# MK70F15WS register map
File version: 1.6
Registers are 32-bit, read-write, reset 0x0 unless marked. A register's access mark holds for its fields unless they carry their own. Offsets are from the block's base; [hi:lo] are bit positions; {n}, {i} and the like mark numbered series.

## SIM — System Integration Module
Base 0x40047000; register names take the prefix SIM_
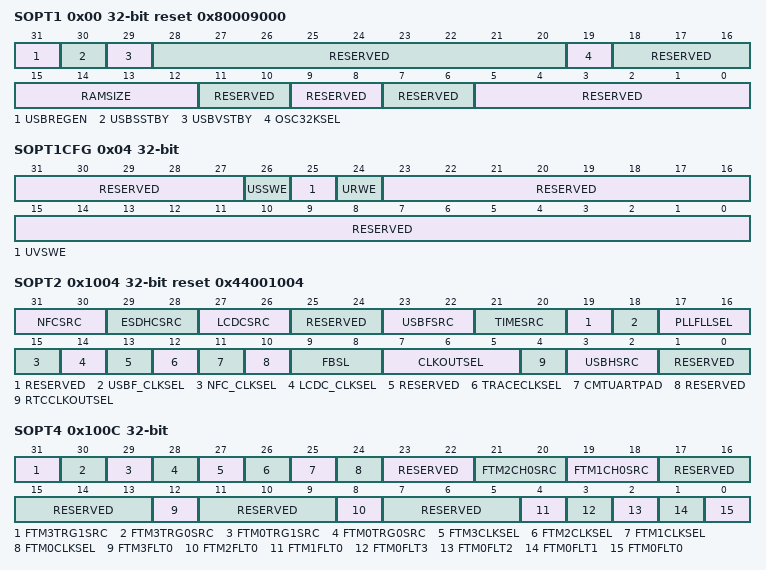
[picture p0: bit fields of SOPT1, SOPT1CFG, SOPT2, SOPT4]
0x00 SOPT1 reset 0x80009000 (reset mask 0xFFFFFFC0) — System Options Register 1
  [31] USBREGEN — USB voltage regulator enable
    0=USB voltage regulator is disabled; 1=USB voltage regulator is enabled
  [30] USBSSTBY — USB voltage regulator in standby mode during Stop, VLPS, LLS or VLLS
    0=USB voltage regulator not in standby during Stop, VLPS, LLS and VLLS modes; 1=USB voltage regulator in standby during Stop, VLPS, LLS and VLLS modes
  [29] USBVSTBY — USB voltage regulator in standby mode during VLPR or VLPW
    0=USB voltage regulator not in standby during VLPR and VLPW modes; 1=USB voltage regulator in standby during VLPR and VLPW modes
  [28:20] RESERVED ro
  [19] OSC32KSEL — 32 kHz oscillator clock select
    0=System oscillator (OSC32KCLK); 1=RTC oscillator
  [18:16] RESERVED ro
  [15:12] RAMSIZE ro
    {v}=Undefined (v=0..8); 9=128 KB; {v}=Undefined (v=10..15)
  [11:10] RESERVED ro
  [9:8] RESERVED ro
  [7:6] RESERVED ro
  [5:0] RESERVED ro
0x04 SOPT1CFG — SOPT1 Configuration Register
  [31:27] RESERVED ro
  [26] USSWE — USB voltage regulator stop standby write enable
    0=SOPT1[USBSSTBY] cannot be written; 1=SOPT1[USBSSTBY] can be written
  [25] UVSWE — USB voltage regulator VLP standby write enable
    0=SOPT1[USBVSTBY] cannot be written; 1=SOPT1[USBVSTBY] can be written
  [24] URWE — USB voltage regulator enable write enable
    0=SOPT1[USBREGEN] cannot be written; 1=SOPT1[USBREGEN] can be written
  [23:0] RESERVED ro
0x1004 SOPT2 reset 0x44001004 — System Options Register 2
  [31:30] NFCSRC — NFC Flash clock source select
    0=Bus clock; 1=MCGPLL0CLK; 2=MCGPLL1CLK; 3=OSC0ERCLK
  [29:28] ESDHCSRC — ESDHC perclk source select
    0=Core/system clock; 1=MCGPLLCLK/MCGFLLCLK selected by PLLFLLSEL[1:0]; 2=OSC0ERCLK; 3=External bypass clock (PTD11)
  [27:26] LCDCSRC — LCDC Pixel clock source select
    0=Bus clock; 1=MCGPLL0CLK; 2=MCGPLL1CLK; 3=OSC0ERCLK
  [25:24] RESERVED ro
  [23:22] USBFSRC — USB FS clock source select
    0=MCGPLLCLK/MCGFLLCLK selected by PLLFLLSEL[1:0]; 1=MCGPLL0CLK; 2=MCGPLL1CLK; 3=OSC0ERCLK
  [21:20] TIMESRC — Ethernet timestamp clock source select
    0=System platform clock; 1=MCGPLLCLK/MCGFLLCLK selected by PLLFLLSEL[1:0]; 2=OSC0ERCLK; 3=External bypass clock (PTE26)
  [19] RESERVED ro
  [18] USBF_CLKSEL — USB FS clock select
    0=External bypass clock (PTE26); 1=Clock divider USB FS clock
  [17:16] PLLFLLSEL — PLL/FLL clock select
    0=MCGFLLCLK; 1=MCGPLL0CLK; 2=MCGPLL1CLK; 3=System Platform clock
  [15] NFC_CLKSEL — NFC Flash clock select
    0=Clock divider NFC clock; 1=EXTAL1 clock
  [14] LCDC_CLKSEL — LCDC pixel clock select
    0=Clock divider LCDC pixel clock; 1=EXTAL1 clock
  [13] RESERVED ro
  [12] TRACECLKSEL — Debug trace clock select
    0=MCGCLKOUT; 1=Core/system clock
  [11] CMTUARTPAD — CMT/UART pad drive strength
    0=Single-pad drive strength for CMT IRO or UART0_TXD; 1=Dual-pad drive strength for CMT IRO or UART0_TXD
  [10] RESERVED ro
  [9:8] FBSL — Flexbus security level
    0=All off-chip accesses (op code and data) via the FlexBus and DDR controller are disallowed; 2=Off-chip op code accesses are disallowed. Data accesses are allowed.; 3=Off-chip op code accesses and data accesses are allowed
  [7:5] CLKOUTSEL — Clock out select
    0=FlexBus clock (reset value); 2=Flash ungated clock; 3=LPO clock (1 kHz); 4=MCGIRCLK; 5=RTC 32 kHz clock; 6=OSC0ERCLK; 7=OSC1ERCLK
  [4] RTCCLKOUTSEL — RTC clock out select
    0=RTC 1 Hz clock drives RTC CLKOUT; 1=RTC 32 kHz oscillator drives RTC CLKOUT
  [3:2] USBHSRC — USB HS clock source select
    0=Bus clock; 1=MCGPLL0CLK; 2=MCGPLL1CLK; 3=OSC0ERCLK
  [1:0] RESERVED ro
0x100C SOPT4 — System Options Register 4
  [31] FTM3TRG1SRC — FlexTimer 3 hardware trigger 1 source select
    0=PDB output trigger 3 drives FTM3 hardware trigger 1; 1=FTM2 channel match trigger drives FTM3 hardware trigger 1
  [30] FTM3TRG0SRC — FlexTimer 3 hardware trigger 0 source select
    0=CMP3 OUT drives FTM3 hardware trigger 0; 1=FTM1 channel match trigger drives FTM3 hardware trigger 0
  [29] FTM0TRG1SRC — FlexTimer 0 hardware trigger 1 source select
    0=PDB output trigger 1 drives FTM0 hardware trigger 1; 1=FTM2 channel match trigger drives FTM0 hardware trigger 1
  [28] FTM0TRG0SRC — FlexTimer 0 hardware trigger 0 source select
    0=CMP0 OUT drives FTM0 hardware trigger 0; 1=FTM1 channel match trigger drives FTM0 hardware trigger 0
  [27] FTM3CLKSEL — FlexTimer 3 external clock pin select
    0=FTM3 external clock driven by FTM CLKIN0 pin; 1=FTM3 external clock driven by FTM CLKIN1 pin 
  [26] FTM2CLKSEL — FlexTimer 2 external clock pin select
    0=FTM2 external clock driven by FTM CLKIN0 pin; 1=FTM2 external clock driven by FTM CLKIN1 pin
  [25] FTM1CLKSEL — FlexTimer 1 external clock pin select
    0=FTM1 external clock driven by FTM CLKIN0 pin; 1=FTM1 external clock driven by FTM CLKIN1 pin
  [24] FTM0CLKSEL — FlexTimer 0 external clock pin select
    0=FTM0 external clock driven by FTM CLKIN0 pin; 1=FTM0 external clock driven by FTM CLKIN1 pin
  [23:22] RESERVED ro
  [21:20] FTM2CH0SRC — FlexTimer 2 channel 0 input capture source select
    0=FTM2_CH0 pin; 1=CMP0 output; 2=CMP1 output
  [19:18] FTM1CH0SRC — FlexTimer 1 channel 0 input capture source select
    0=FTM1_CH0 pin; 1=CMP0 output; 2=CMP1 output; 3=USB SOF trigger
  [17:13] RESERVED ro
  [12] FTM3FLT0 — FlexTimer 3 Fault 0 Select.
    0=FTM3_FLT0 drives FTM 2 fault 0; 1=CMP0 OUT drives FTM 2 fault 0
  [11:9] RESERVED ro
  [8] FTM2FLT0 — FlexTimer 2 Fault 0 Select
    0=FTM2_FLT0 drives FTM 2 fault 0; 1=CMP0 OUT drives FTM 2 fault 0
  [7:5] RESERVED ro
  [4] FTM1FLT0 — FlexTimer 1 Fault 0 Select
    0=FTM1_FLT0 drives FTM 1 fault 0; 1=CMP0 OUT drives FTM 1 fault 0
  [3] FTM0FLT3 — FlexTimer 0 Fault 3 Select.
    0=FTM0_FLT3 drives FTM 0 fault 3; 1=CMP0 OUT drives FTM 0 fault 3
  [2] FTM0FLT2 — FlexTimer 0 Fault 2 Select
    0=FTM0_FLT2 drives FTM 0 fault 2; 1=CMP2 OUT drives FTM 0 fault 2
  [1] FTM0FLT1 — FlexTimer 0 Fault 1 Select
    0=FTM0_FLT1 drives FTM 0 fault 1; 1=CMP1 OUT drives FTM 0 fault 1
  [0] FTM0FLT0 — FlexTimer 0 Fault 0 Select
    0=FTM0_FLT0 drives FTM 0 fault 0; 1=CMP0 OUT drives FTM 0 fault 0
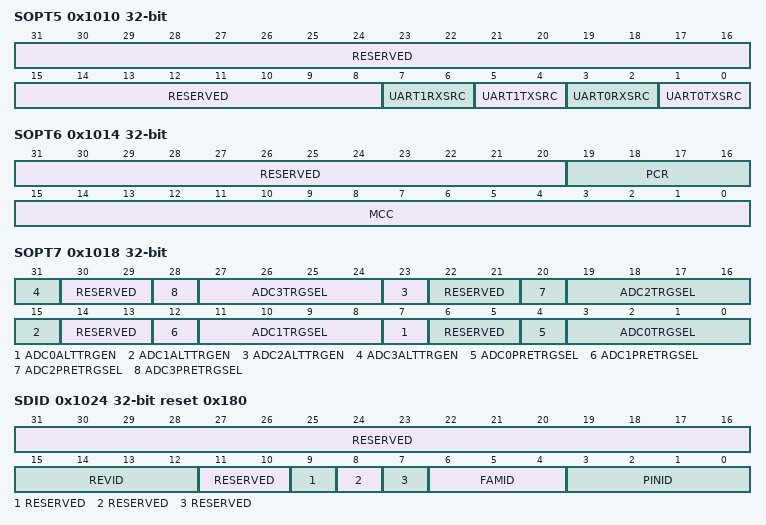
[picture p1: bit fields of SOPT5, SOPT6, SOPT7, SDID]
0x1010 SOPT5 (reset mask 0xFF) — System Options Register 5
  [31:8] RESERVED ro
  [7:6] UART1RXSRC — UART1 receive data source select
    0=UART1_RX pin; 1=CMP0; 2=CMP1
  [5:4] UART1TXSRC — UART1 transmit data source select
    0=UART1_TX pin; 1=UART1_TX pin modulated with FTM1 channel 0 Output; 2=UART1_TX pin modulated with FTM2 channel 0 Output
  [3:2] UART0RXSRC — UART0 receive data source select
    0=UART0_RX pin; 1=CMP0; 2=CMP1
  [1:0] UART0TXSRC — UART0 transmit data source select
    0=UART0_TX pin; 1=UART0_TX pin modulated with FTM1 channel 0 output; 2=UART0_TX pin modulated with FTM2 channel 0 output
0x1014 SOPT6 — System Options Register 6
  [31:20] RESERVED ro, [19:16] PCR, [15:0] MCC
0x1018 SOPT7 — System Options Register 7
  [8n+7] ADC{n}ALTTRGEN (n=0..3) — ADC{n} alternate trigger enable
    0=PDB trigger selected for ADC{n}; 1=Alternate trigger selected for ADC{n}
  [30:29] RESERVED ro
  [8n+4] ADC{n}PRETRGSEL (n=0..3) — ADC{n} pre-trigger select
    0=Pre-trigger A selected for ADC{n}; 1=Pre-trigger B selected for ADC{n}
  [8n+3:8n] ADC{n}TRGSEL (n=0..3) — ADC{n} trigger select
    0=External trigger; 1=High speed comparator 0 asynchronous interrupt; 2=High speed comparator 1 asynchronous interrupt; 3=High speed comparator 2 asynchronous interrupt; {v}=PIT trigger {v-4} (v=4..7); {v}=FTM{v-8} trigger (v=8..11); 12=RTC alarm; 13=RTC seconds; 14=Low-power timer trigger; 15=High speed comparator 3 asynchronous interrupt
  [22:21] RESERVED ro
  [14:13] RESERVED ro
  [6:5] RESERVED ro
0x1024 SDID ro reset 0x180 (reset mask 0xFFFFFF80) — System Device Identification Register
  [31:16] RESERVED
  [15:12] REVID — Device revision number
  [11:10] RESERVED
  [9] RESERVED
  [8] RESERVED
  [7] RESERVED
  [6:4] FAMID — Kinetis family identification
    0=K10; 1=K20; 2=K61; 4=K60; 5=K70
  [3:0] PINID — Pincount identification
    10=144-pin; 12=196-pin; 14=256-pin
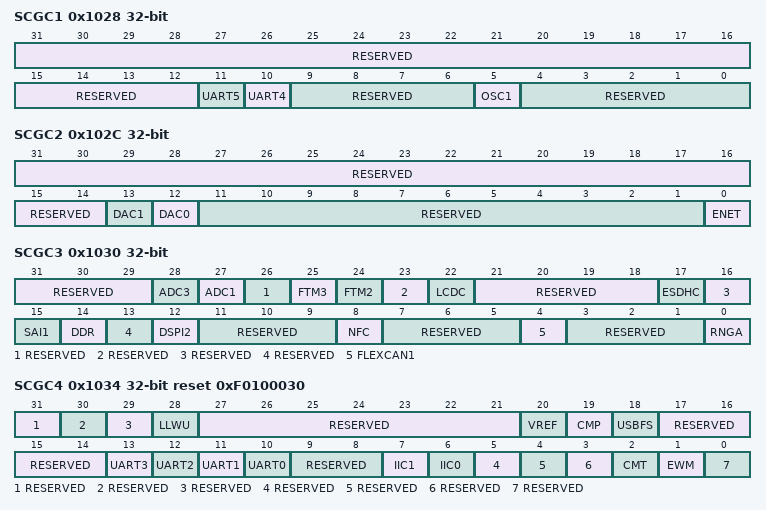
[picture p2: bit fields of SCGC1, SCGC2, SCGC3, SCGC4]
0x1028 SCGC1 — System Clock Gating Control Register 1
  [31:12] RESERVED ro
  [11] UART5 — UART5 clock gate control
    0=Clock is disabled; 1=Clock is enabled
  [10] UART4 — UART4 clock gate control
    0=Clock is disabled; 1=Clock is enabled
  [9:6] RESERVED ro
  [5] OSC1 — OSC1 clock gate control
    0=Clock is disabled; 1=Clock is enabled
  [4:0] RESERVED ro
0x102C SCGC2 — System Clock Gating Control Register 2
  [31:14] RESERVED ro
  [13] DAC1 — 12BDAC1 clock gate control
    0=Clock is disabled; 1=Clock is enabled
  [12] DAC0 — 12BDAC0 clock gate control
    0=Clock is disabled; 1=Clock is enabled
  [11:1] RESERVED ro
  [0] ENET — ENET clock gate control
    0=Clock is disabled; 1=Clock is enabled
0x1030 SCGC3 — System Clock Gating Control Register 3
  [31:29] RESERVED ro
  [28] ADC3 — ADC3 clock gate control
    0=Clock is disabled; 1=Clock is enabled
  [27] ADC1 — ADC1 clock gate control
    0=Clock is disabled; 1=Clock is enabled
  [26] RESERVED ro
  [25] FTM3 — FTM3 clock gate control
    0=Clock is disabled; 1=Clock is enabled
  [24] FTM2 — FTM2 clock gate control
    0=Clock is disabled; 1=Clock is enabled
  [23] RESERVED ro
  [22] LCDC — LCDC clock gate control
    0=Clock is disabled; 1=Clock is enabled
  [21:18] RESERVED ro
  [17] ESDHC — ESDHC clock gate control
    0=Clock is disabled; 1=Clock is enabled
  [16] RESERVED ro
  [15] SAI1 — SAI1 clock gate control
    0=Clock is disabled; 1=Clock is enabled
  [14] DDR — DDR clock gate control
    0=Clock is disabled; 1=Clock is enabled
  [13] RESERVED ro
  [12] DSPI2 — DSPI2 clock gate control
    0=Clock is disabled; 1=Clock is enabled
  [11:9] RESERVED ro
  [8] NFC — NFC clock gate control
    0=Clock is disabled; 1=Clock is enabled
  [7:5] RESERVED ro
  [4] FLEXCAN1 — FlexCAN1 clock gate control
    0=Clock is disabled; 1=Clock is enabled
  [3:1] RESERVED ro
  [0] RNGA — RNGA clock gate control
    0=Clock is disabled; 1=Clock is enabled
0x1034 SCGC4 reset 0xF0100030 — System Clock Gating Control Register 4
  [31] RESERVED ro
  [30] RESERVED ro
  [29] RESERVED ro
  [28] LLWU — LLWU Clock Gate Control
    0=Clock is disabled; 1=Clock is enabled
  [27:21] RESERVED ro
  [20] VREF — VREF clock gate control
    0=Clock is disabled; 1=Clock is enabled
  [19] CMP — Comparator clock gate control
    0=Clock is disabled; 1=Clock is enabled
  [18] USBFS — USB FS clock gate control
    0=Clock is disabled; 1=Clock is enabled
  [17:14] RESERVED ro
  [n+10] UART{n} (n=0..3) — UART{n} clock gate control
    0=Clock is disabled; 1=Clock is enabled
  [9:8] RESERVED ro
  [7] IIC1 — IIC1 clock gate control
    0=Clock is disabled; 1=Clock is enabled
  [6] IIC0 — IIC0 clock gate control
    0=Clock is disabled; 1=Clock is enabled
  [5] RESERVED ro
  [4] RESERVED ro
  [3] RESERVED ro
  [2] CMT — CMT clock gate control
    0=Clock is disabled; 1=Clock is enabled
  [1] EWM — EWM clock gate control
    0=Clock is disabled; 1=Clock is enabled
  [0] RESERVED ro
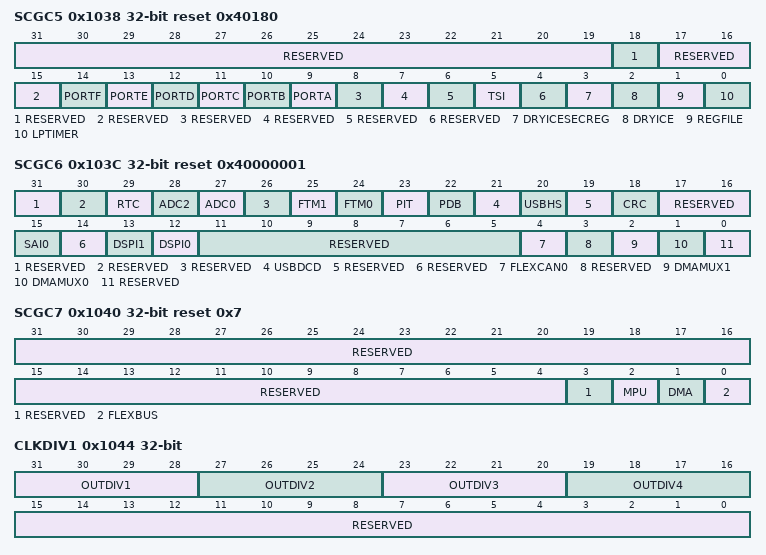
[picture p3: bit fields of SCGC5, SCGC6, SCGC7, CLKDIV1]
0x1038 SCGC5 reset 0x40180 — System Clock Gating Control Register 5
  [31:19] RESERVED ro
  [18] RESERVED ro
  [17:15] RESERVED ro
  [14] PORTF — PORTF clock gate control
    0=Clock is disabled; 1=Clock is enabled
  [13] PORTE — PORTE clock gate control
    0=Clock is disabled; 1=Clock is enabled
  [12] PORTD — PORTD clock gate control
    0=Clock is disabled; 1=Clock is enabled
  [11] PORTC — PORTC clock gate control
    0=Clock is disabled; 1=Clock is enabled
  [10] PORTB — PORTB clock gate control
    0=Clock is disabled; 1=Clock is enabled
  [9] PORTA — PORTA clock gate control
    0=Clock is disabled; 1=Clock is enabled
  [8] RESERVED ro
  [7] RESERVED ro
  [6] RESERVED ro
  [5] TSI — TSI clock gate control
    0=Clock is disabled; 1=Clock is enabled
  [4] RESERVED ro
  [3] DRYICESECREG — Dryice secure storage clock gate control
    0=Clock is disabled; 1=Clock is enabled
  [2] DRYICE — Dryice clock gate control
    0=Clock is disabled; 1=Clock is enabled
  [1] REGFILE — Register File Clock Gate Control
    0=Clock is disabled; 1=Clock is enabled
  [0] LPTIMER — LPTMR clock gate control
    0=Clock is disabled; 1=Clock is enabled
0x103C SCGC6 reset 0x40000001 — System Clock Gating Control Register 6
  [31] RESERVED ro
  [30] RESERVED ro
  [29] RTC — RTC clock gate control
    0=Clock is disabled; 1=Clock is enabled
  [28] ADC2 — ADC2 clock gate control
    0=Clock is disabled; 1=Clock is enabled
  [27] ADC0 — ADC0 clock gate control
    0=Clock is disabled; 1=Clock is enabled
  [26] RESERVED ro
  [25] FTM1 — FTM1 clock gate control
    0=Clock is disabled; 1=Clock is enabled
  [24] FTM0 — FTM0 clock gate control
    0=Clock is disabled; 1=Clock is enabled
  [23] PIT — PIT clock gate control
    0=Clock is disabled; 1=Clock is enabled
  [22] PDB — PDB clock gate control
    0=Clock is disabled; 1=Clock is enabled
  [21] USBDCD — USB DCD clock gate control
    0=Clock is disabled; 1=Clock is enabled
  [20] USBHS — USBHS clock gate control
    0=Clock is disabled; 1=Clock is enabled
  [19] RESERVED ro
  [18] CRC — CRC clock gate control
    0=Clock is disabled; 1=Clock is enabled
  [17:16] RESERVED ro
  [15] SAI0 — SAI0 clock gate control
    0=Clock is disabled; 1=Clock is enabled
  [14] RESERVED ro
  [13] DSPI1 — DSPI1 clock gate control
    0=Clock is disabled; 1=Clock is enabled
  [12] DSPI0 — DSPI0 clock gate control
    0=Clock is disabled; 1=Clock is enabled
  [11:5] RESERVED ro
  [4] FLEXCAN0 — FlexCAN0 clock gate control
    0=Clock is disabled; 1=Clock is enabled
  [3] RESERVED ro
  [2] DMAMUX1 — DMAMUX1 clock gate control
    0=Clock is disabled; 1=Clock is enabled
  [1] DMAMUX0 — DMAMUX0 clock gate control
    0=Clock is disabled; 1=Clock is enabled
  [0] RESERVED ro
0x1040 SCGC7 reset 0x7 — System Clock Gating Control Register 7
  [31:4] RESERVED ro
  [3] RESERVED ro
  [2] MPU — MPU clock gate control
    0=Clock is disabled; 1=Clock is enabled
  [1] DMA — DMA controller clock gate control
    0=Clock is disabled; 1=Clock is enabled
  [0] FLEXBUS — FlexBus controller clock gate control
    0=Clock is disabled; 1=Clock is enabled
0x1044 CLKDIV1 (reset mask 0xFFFF) — System Clock Divider Register 1
  [35-4n:32-4n] OUTDIV{n} (n=1..4) — Clock {n} output divider value
    {v}=Divide-by-{v+1} (v=0..15)
  [15:0] RESERVED ro
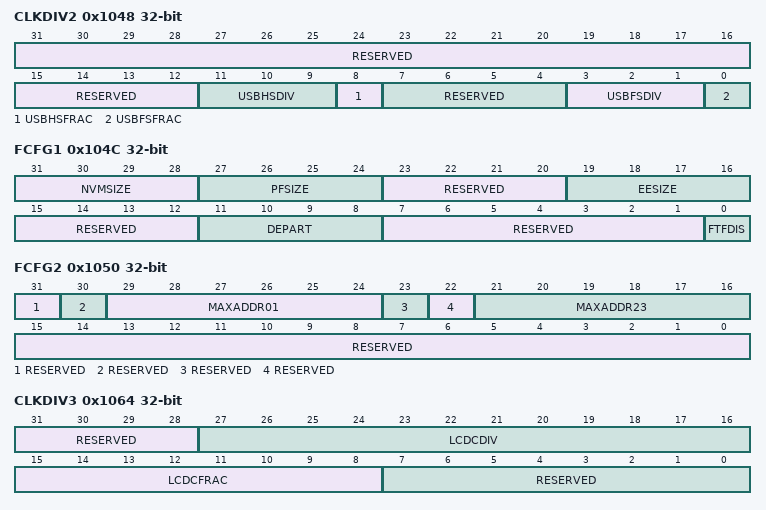
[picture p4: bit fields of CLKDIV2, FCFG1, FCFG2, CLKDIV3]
0x1048 CLKDIV2 — System Clock Divider Register 2
  [31:12] RESERVED ro
  [11:9] USBHSDIV — USB HS clock divider divisor
  [8] USBHSFRAC — USB HS clock divider fraction
  [7:4] RESERVED ro
  [3:1] USBFSDIV — USB FS clock divider divisor
  [0] USBFSFRAC — USB FS clock divider fraction
0x104C FCFG1 (reset mask 0xF0F0FF) — Flash Configuration Register 1
  [31:28] NVMSIZE ro — FlexNVM size
    0=0 KB; 11=512 KB, 16 KB protection region; 15=512 KB, 16 KB protection region
  [27:24] PFSIZE ro — Program flash size
    11=512 KB, 16 KB protection size; 13=1024 KB, 32 KB protection size; 15=1024 KB, 32 KB protection size
  [23:20] RESERVED ro
  [19:16] EESIZE ro — EEPROM size
    0=16 KB; 1=8 KB; 2=4 KB; 3=2 KB; 4=1 KB; 5=512 Bytes; 6=256 Bytes; 7=128 Bytes; 8=64 Bytes; 9=32 Bytes; 15=0 Bytes
  [15:12] RESERVED ro
  [11:8] DEPART ro — FlexNVM partition
  [7:1] RESERVED ro
  [0] FTFDIS — Disable FTFE
0x1050 FCFG2 ro (reset mask 0xC0C0FFFF) — Flash Configuration Register 2
  [31] RESERVED
  [30] RESERVED
  [29:24] MAXADDR01 — Max address block 0 or 1
  [23] RESERVED
  [22] RESERVED
  [21:16] MAXADDR23 — Max address block 2 or 3
  [15:0] RESERVED
0x1054 UIDH ro reset not defined — Unique Identification Register High
  [31:0] UID — Unique Identification
0x1058 UIDMH ro reset not defined — Unique Identification Register Mid-High
  [31:0] UID — Unique Identification
0x105C UIDML ro reset not defined — Unique Identification Register Mid Low
  [31:0] UID — Unique Identification
0x1060 UIDL ro reset not defined — Unique Identification Register Low
  [31:0] UID — Unique Identification
0x1064 CLKDIV3 — System Clock Divider Register 3
  [31:28] RESERVED ro
  [27:16] LCDCDIV — LCDC Clock divder fraction
  [15:8] LCDCFRAC — LCDCFRAC clock divider fraction.
  [7:0] RESERVED ro
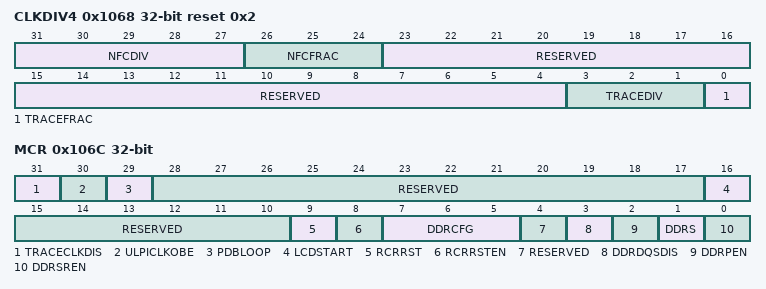
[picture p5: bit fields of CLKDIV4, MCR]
0x1068 CLKDIV4 reset 0x2 — System Clock Divider Register 4
  [31:27] NFCDIV — NFC clock divider divisor
  [26:24] NFCFRAC — NFC clock divider fraction
  [23:4] RESERVED ro
  [3:1] TRACEDIV — Trace clock divider divisor
  [0] TRACEFRAC — Trace clock divider fraction
0x106C MCR — Misc Control Register
  [31] TRACECLKDIS — Trace clock disable.
    0=Enables trace clock; 1=Disable trace clock
  [30] ULPICLKOBE — 60 MHz ULPI clock (ULPI_CLK) output enable
    0=Internal generated 60MHz ULPI clock is not output to the ULPI_CLK pin; 1=Interanl generated 60MHz ULPI clock provide clock for external ULPI phy
  [29] PDBLOOP — PDB Loop Mode
    0=Provides two seperated minor loop, loop for ADC0/1 and loop for ADC2/3D; 1=Provides a loop to involve ADC0, ADC1, ADC2 and ADC3
  [28:17] RESERVED ro
  [16] LCDSTART — Start LCDC display
    0=Stops LCDC display; 1=Starts LCDC display
  [15:10] RESERVED ro
  [9] RCRRST ro — DDR RCR Reset Status
    0=DDR RCR is not in reset status; 1=DDR RCR is in reset status
  [8] RCRRSTEN — DDR RCR Special Reset Enable
    0=No soft reset to DDR RCR; 1=Soft reset to DDR RCR
  [7:5] DDRCFG — DDR configuration select
    0=LPDDR Half Strength; 1=LPDDR Full Strength; 2=DDR2 Half Strength; 3=DDR1; 6=DDR2 Full Strength
  [4] RESERVED wo
  [3] DDRDQSDIS — DDR_DQS analog circuit disable
  [2] DDRPEN — Pin enable for all DDR I/O
    0=All DDR I/O pins are disabled; 1=All DDR I/O pins are enabled
  [1] DDRS ro — DDR Self Refresh Status
    0=DDR is not set to self refresh mode; 1=Sets DDR in self refresh mode
  [0] DDRSREN — DDR self refresh enable
    0=DDR is not set to self refresh mode; 1=DDR is set in self refresh mode. Check DDRS to make sure DDR is in self refresh mode.
